# nrf7140_application register map
Vendor: Nordic Semiconductor; Series: nRF71; File version: 1
CPU: CM33 r0p4, little endian, MPU, FPU, 3 interrupt priority bits, 480 interrupts, 8 SAU regions
Registers are 32-bit, read-write, reset 0x0 unless marked. A register's access mark holds for its fields unless they carry their own. Offsets are from the block's base; [hi:lo] are bit positions; lines under a group give offsets from that group; {n}, {i} and the like mark numbered series; 'fields as' and 'values as' point back to an identical list.

## GLOBAL_QSPI120_NS — Quad serial peripheral interface 0
Base 0x4F8D7000
Same registers: GLOBAL_QSPI121_NS 0x4F8DF000, GLOBAL_QSPI120_S 0x5F8D7000, GLOBAL_QSPI121_S 0x5F8DF000
0x00 TASKS_START wo — Start operation.
  [0] TASKS_START
    1=Trigger task
0x100 EVENTS_CORE — Interrupt from the QSPI core
  [0] EVENTS_CORE
    0=NotGenerated (Event not generated); 1=Generated (Event generated)
0x104 EVENTS_DMA group — Peripheral events.
  0x00 EVENTS_DONE group — Peripheral events.
    0x00 LIST — Descriptor list is complete.
      [0] LIST
        values as EVENTS_CORE.EVENTS_CORE
    0x04 LISTPART — Descriptor list is partially complete. Threshold in CONFIG.LISTPARTTHRESH register has been passed.
      [0] LISTPART
        values as EVENTS_CORE.EVENTS_CORE
    0x08 SELECTJOB — Selected job is completed. Selection is done via CONFIG.SELECTJOBENABLE.
      [0] SELECTJOB
        values as EVENTS_CORE.EVENTS_CORE
    0x0C DATA — A job has been completed, i.e. the job's data has been completely transferred either to AXI or DMA bus, depending on direction.
      [0] DATA
        values as EVENTS_CORE.EVENTS_CORE
    0x10 JOB — A job has been fetched from the joblist.
      [0] JOB
        values as EVENTS_CORE.EVENTS_CORE
  0x14 ERROR — AXI bus error received.
    [0] ERROR
      values as EVENTS_CORE.EVENTS_CORE
  0x18 PAUSED — DMA paused with task TASKS_PAUSE.
    [0] PAUSED
      values as EVENTS_CORE.EVENTS_CORE
  0x1C RESET — DMA reset with task TASKS_RESET.
    [0] RESET
      values as EVENTS_CORE.EVENTS_CORE
  0x20 DONE — DMA transfer done
    [0] DONE
      values as EVENTS_CORE.EVENTS_CORE
  0x24 TXUNEXPECTEDIDLE — The QSPI core has gone into idle state at an unexpected time, this can happen if the TX buffer underflows, this event is followed by either DONE or ABORTED event. Triggered by the CORE being idle while we still have data to transfer to the CORE.
    [0] TXUNEXPECTEDIDLE
      values as EVENTS_CORE.EVENTS_CORE
  0x28 INTERNALBUSERROR — An error occured during the transfer of data internally in the QSPI, followed by either DONE or ABORTED event. This event is generated on an AHB error response on the easyDMA towards the QSPI CORE. The BUSERROR address is not given in a register since the target register address is fixed.
    [0] INTERNALBUSERROR
      values as EVENTS_CORE.EVENTS_CORE
  0x2C ABORTED — The QSPI DMA has aborted due to an error given in a separate event, and has attempted to complete any ongoing transactions, and stopped. The QSPI DMA is ready for a new transaction.
    [0] ABORTED
      values as EVENTS_CORE.EVENTS_CORE
0x200 SHORTS — Shortcuts between local events and tasks
  [0] DMA_DONE_START — Shortcut between event DMA.DONE and task START
    0=Disabled (Disable shortcut); 1=Enabled (Enable shortcut)
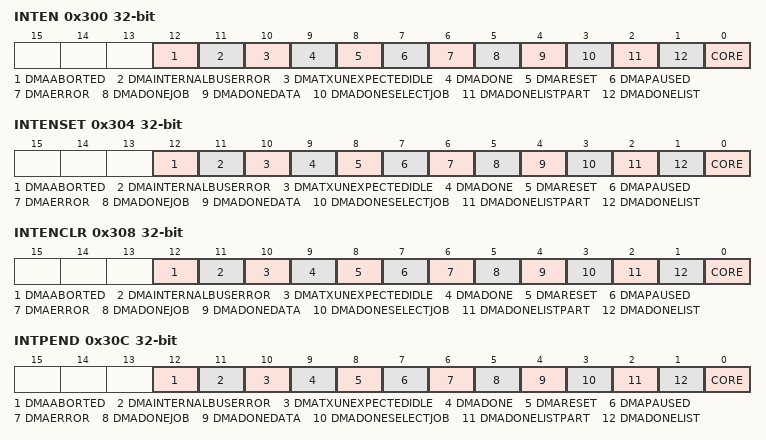
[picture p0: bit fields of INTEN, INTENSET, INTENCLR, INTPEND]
0x300 INTEN — Enable or disable interrupt
  [all] fields
    0=Disabled; 1=Enabled
  [12] DMAABORTED — Enable or disable interrupt for event DMAABORTED
  [11] DMAINTERNALBUSERROR — Enable or disable interrupt for event DMAINTERNALBUSERROR
  [10] DMATXUNEXPECTEDIDLE — Enable or disable interrupt for event DMATXUNEXPECTEDIDLE
  [9] DMADONE — Enable or disable interrupt for event DMADONE
  [8] DMARESET — Enable or disable interrupt for event DMARESET
  [7] DMAPAUSED — Enable or disable interrupt for event DMAPAUSED
  [6] DMAERROR — Enable or disable interrupt for event DMAERROR
  [5] DMADONEJOB — Enable or disable interrupt for event DMADONEJOB
  [4] DMADONEDATA — Enable or disable interrupt for event DMADONEDATA
  [3] DMADONESELECTJOB — Enable or disable interrupt for event DMADONESELECTJOB
  [2] DMADONELISTPART — Enable or disable interrupt for event DMADONELISTPART
  [1] DMADONELIST — Enable or disable interrupt for event DMADONELIST
  [0] CORE — Enable or disable interrupt for event CORE
0x304 INTENSET — Enable interrupt
  [all] fields
    on read: 0=Disabled (Read: Disabled); 1=Enabled (Read: Enabled) | on write: 1=Set (Enable)
  [12] DMAABORTED — Write '1' to enable interrupt for event DMAABORTED
  [11] DMAINTERNALBUSERROR — Write '1' to enable interrupt for event DMAINTERNALBUSERROR
  [10] DMATXUNEXPECTEDIDLE — Write '1' to enable interrupt for event DMATXUNEXPECTEDIDLE
  [9] DMADONE — Write '1' to enable interrupt for event DMADONE
  [8] DMARESET — Write '1' to enable interrupt for event DMARESET
  [7] DMAPAUSED — Write '1' to enable interrupt for event DMAPAUSED
  [6] DMAERROR — Write '1' to enable interrupt for event DMAERROR
  [5] DMADONEJOB — Write '1' to enable interrupt for event DMADONEJOB
  [4] DMADONEDATA — Write '1' to enable interrupt for event DMADONEDATA
  [3] DMADONESELECTJOB — Write '1' to enable interrupt for event DMADONESELECTJOB
  [2] DMADONELISTPART — Write '1' to enable interrupt for event DMADONELISTPART
  [1] DMADONELIST — Write '1' to enable interrupt for event DMADONELIST
  [0] CORE — Write '1' to enable interrupt for event CORE
0x308 INTENCLR — Disable interrupt
  [all] fields
    on read: 0=Disabled (Read: Disabled); 1=Enabled (Read: Enabled) | on write: 1=Clear (Disable)
  [12] DMAABORTED — Write '1' to disable interrupt for event DMAABORTED
  [11] DMAINTERNALBUSERROR — Write '1' to disable interrupt for event DMAINTERNALBUSERROR
  [10] DMATXUNEXPECTEDIDLE — Write '1' to disable interrupt for event DMATXUNEXPECTEDIDLE
  [9] DMADONE — Write '1' to disable interrupt for event DMADONE
  [8] DMARESET — Write '1' to disable interrupt for event DMARESET
  [7] DMAPAUSED — Write '1' to disable interrupt for event DMAPAUSED
  [6] DMAERROR — Write '1' to disable interrupt for event DMAERROR
  [5] DMADONEJOB — Write '1' to disable interrupt for event DMADONEJOB
  [4] DMADONEDATA — Write '1' to disable interrupt for event DMADONEDATA
  [3] DMADONESELECTJOB — Write '1' to disable interrupt for event DMADONESELECTJOB
  [2] DMADONELISTPART — Write '1' to disable interrupt for event DMADONELISTPART
  [1] DMADONELIST — Write '1' to disable interrupt for event DMADONELIST
  [0] CORE — Write '1' to disable interrupt for event CORE
0x30C INTPEND ro — Pending interrupts
  [all] fields
    on read: 0=NotPending (Read: Not pending); 1=Pending (Read: Pending)
  [12] DMAABORTED — Read pending status of interrupt for event DMAABORTED
  [11] DMAINTERNALBUSERROR — Read pending status of interrupt for event DMAINTERNALBUSERROR
  [10] DMATXUNEXPECTEDIDLE — Read pending status of interrupt for event DMATXUNEXPECTEDIDLE
  [9] DMADONE — Read pending status of interrupt for event DMADONE
  [8] DMARESET — Read pending status of interrupt for event DMARESET
  [7] DMAPAUSED — Read pending status of interrupt for event DMAPAUSED
  [6] DMAERROR — Read pending status of interrupt for event DMAERROR
  [5] DMADONEJOB — Read pending status of interrupt for event DMADONEJOB
  [4] DMADONEDATA — Read pending status of interrupt for event DMADONEDATA
  [3] DMADONESELECTJOB — Read pending status of interrupt for event DMADONESELECTJOB
  [2] DMADONELISTPART — Read pending status of interrupt for event DMADONELISTPART
  [1] DMADONELIST — Read pending status of interrupt for event DMADONELIST
  [0] CORE — Read pending status of interrupt for event CORE
0x400 ENABLE — Enables the QSPI This requests clock for the IP core
  [0] ENABLE — Enable the QSPI
0x404 CONFIG group — Unspecified
  0x00 TXBURSTLENGTH reset 0x8 — Transmit burst length
    [4:0] AMOUNT — Number of buffer lines
  0x04 RXBURSTLENGTH reset 0x8 — Receive burst length
    [4:0] AMOUNT — Number of buffer lines
  0x08 RXTRANSFERLENGTH reset 0x10 — Receive transfer full length
    [17:0] AMOUNT — Number of buffer lines
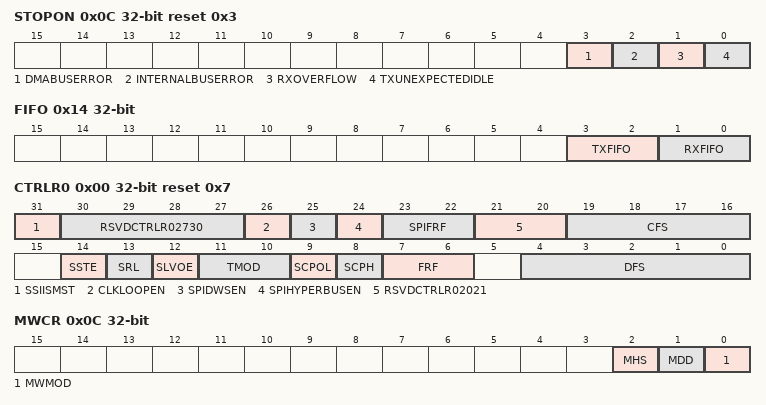
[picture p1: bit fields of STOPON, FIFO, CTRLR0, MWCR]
  0x0C STOPON reset 0x3 — Stop the DMA if the CORE goes into any of the enabled states.
    [3] DMABUSERROR — Terminate the transaction if a DMA.ERROR event is detected.
      0=Disabled; 1=Enabled
    [2] INTERNALBUSERROR — Terminate the transaction if a INTERNALBUSERROR event is detected.
      0=Disabled; 1=Enabled
    [1] RXOVERFLOW — This condition occurrs if the DMA attempts to write to the RX buffer in the CORE, but the buffer is full. When this bit is enabled the DMA will stop when the CORE buffer experiences a rx buffer overflow
      0=Disabled (Stop on rx overflow disabled.); 1=Enabled (Stop on rx overflow enabled.)
    [0] TXUNEXPECTEDIDLE — The CORE will go into idle if the CORE buffer is emptied, if the DMA still has data to transfer the CORE is not expected to go into idle state. This constitutes a buffer underflow. The CORE migth also go into idle if an error occurs.
      0=Disabled (Stop on tx unexpected idle disabled.); 1=Enabled (Stop on tx unexpected idle enabled.)
  0x10 AXIMODE — Determines if AXI-lite or full AXI is used.
    [4] AXIMODE — Type of AXI access.
      0=Lite (AXI Lite); 1=Full AXI
0x418 FORMAT group — Unspecified
  0x00 DFS — Data frame size
    [5:0] DFS
  0x04 BPP — Bits per pixel
    [5:0] BPP
      0=Reordering of pixels disabled; 4=4 Bits per pixel; 8=8 Bits per pixel; 16=16 Bits per pixel
  0x08 PIXELS — Number of pixels following the command
    [17:0] PIXELS — Number of pixels
  0x0C CILEN — Command/Instruction length
    [1:0] CILEN — Number of words
0x500 DMA group — Unspecified
  0x00 STATUS group — EasyVDMA status registers.
    0x00 BYTECOUNT ro — Number of bytes sent or received during processing of current descriptor list
    0x04 ATTRIBUTE ro — Latest job attribute being processed.
      [5:0] ATTRIBUTE
    0x08 ADDRESS ro — Latest address being accessed.
    0x0C JOBCOUNT ro — Number of completed jobs in current descriptor list.
    0x10 BUSERROR ro — AXI bus error status.
      [2:0] BUSERROR — AXI bus error type
        0=NoError (There are no errors.); 1=ReadError (Error related to memory when reading joblist, or error related to memory/register when reading data.); 2=ReadDecodeError (Error related to the joblist address when reading joblist, or error related to address when reading memory/register.); 3=WriteError (Error related to memory/register when writing data.); 4=WriteDecodeError (Error related to the memory/register address when writing data.)
    0x14 FIFO ro — Data fifo status.
      [3:2] TXFIFO — Peripheral-to-Memory direction data fifo status
        0=Empty (Fifo is empty.); 1=NotEmpty (Fifo contains data.); 2=Full (Fifo is full.)
      [1:0] RXFIFO — Memory-to-Peripheral direction data fifo status
        values as TXFIFO
    0x18 ACTIVE ro — DMA activity state.
      [0] ACTIVE
        0=Idle (DMA is in idle state.); 1=Active (Data is being transferred.)
  0x100 CONFIG group — General config registers
    0x00 BUFFERFILL — Data to be used when data is sent with BufferFill attribute
      [7:0] BUFFERFILL
    0x04 LISTPTR — Start address of descriptor list
    0x08 LISTPARTTHRESH — Threshold value for generating event EVENTS_DONE.PARTLIST when descriptor list is partially completed. Value is number of jobs.
      [15:0] LISTPARTTHRESH — Threshold value.
0x900 CORE group — Unspecified
  0x00 CORE group — Unspecified
    0x00 CTRLR0 reset 0x7 — Control Register 0
      [31] SSIISMST ro — This field selects if QSPI CORE is working in Controller or Target mode
        0=TARGET (QSPI CORE is Target); 1=CONTROLLER (QSPI CORE is Controller)
      [30:27] RSVDCTRLR02730 ro
      [26] CLKLOOPEN ro — Clock loop back enable bit. Once this bit is set to 1, QSPI CORE will use looped back clock (mst_sclk_in) to capture read data
        0=DISABLE (Disable Clock Loop Back); 1=ENABLE (Enable Clock Loop Back)
      [25] SPIDWSEN — Enable Dynamic wait states in SPI mode of operation. This field is only applicable when CTRLR0.FRF is set to 0 (Motorola SPI Frame Format).
        0=DISABLE (Disable SPI Dynamic Wait State); 1=ENABLE (Enable SPI Dynamic Wait State)
      [24] SPIHYPERBUSEN ro — SPI Hyperbus Frame format enable.
        0=DISABLE (Disable Hyperbus Format); 1=ENABLE (Enable Hyperbus Format)
      [23:22] SPIFRF — SPI Frame Format
        0=SPISTANDARD (Standard SPI Format); 1=SPIDUAL (Dual SPI Format); 2=SPIQUAD (Quad SPI Format); 3=SPIOCTAL (Octal SPI Format)
      [21:20] RSVDCTRLR02021 ro
      [19:16] CFS — Control Frame Size.
        {v}=SIZE{v+1:02}BIT ({v+1:02}-bit Control Word) (v=0..15)
      [14] SSTE — Target Select Toggle Enable.
        0=TOGGLEDISABLE (ss_*_n will stay low and sclk will run continuously for the duration of the transfer); 1=TOGGLEEN (ss_*_n line will toggle between consecutive data frames, with the serial clock (sclk) being held to its default value while ss_*_n is high)
      [13] SRL — Shift Register Loop.
        0=NORMALMODE (Normal mode operation); 1=TESTINGMODE (Test Mode Operation)
      [12] SLVOE — Target Output Enable.
        0=ENABLED (Target Output is enabled); 1=DISABLED (Target Output is disabled)
      [11:10] TMOD — Transfer Mode.
        0=TXANDRX (Transmit & Receive; Not Applicable in enhanced SPI operating mode or when SSIC_HAS_TX_RX_EN is set to 0); 1=TXONLY (Transmit only mode; Or Write in enhanced SPI operating mode); 2=RXONLY (Receive only mode; Or Read in enhanced SPI operating mode); 3=EEPROMREAD (EEPROM Read mode; Not Applicable in enhanced SPI operating mode)
      [9] SCPOL — Serial Clock Polarity.
        0=INACTIVEHIGH (Inactive state of serial clock is low); 1=INACTIVELOW (Inactive state of serial clock is high)
      [8] SCPH — Serial Clock Phase.
        0=MIDDLEBIT (Serial clock toggles in middle of first bit); 1=STARTBIT (Serial clock toggles at start of first bit)
      [7:6] FRF — Frame Format.
        0=SPI (Motorola SPI Frame Format); 1=SSP (Texas Instruments SSP Frame Format); 2=MICROWIRE (National Semiconductors Microwire Frame Format)
      [4:0] DFS — Data Frame Size.
        {v}=DFS{v+1:02}BIT ({v+1:02}-bit serial data transfer) (v=3..31)
    0x04 CTRLR1 — Control Register 1
      [15:0] NDF — Number of Data Frames.
    0x08 SSIENR — SSI Enable Register
      [0] SSICEN — SSI Enable.
        0=DISABLE (Disables QSPI CORE); 1=ENABLED (Enables QSPI CORE)
    0x0C MWCR — Microwire Control Register
      [2] MHS — Microwire Handshaking.
        0=DISABLE (handshaking interface is disabled); 1=ENABLED (handshaking interface is enabled)
      [1] MDD — Microwire Control.
        0=RECEIVE (SSI receives data); 1=TRANSMIT (SSI transmits data)
      [0] MWMOD — Microwire Transfer Mode.
        0=NONSEQUENTIAL (Non-Sequential Transfer); 1=SEQUENTIAL (Sequential Transfer)
    0x10 SER — Target Enable Register
      [3:0] SER — Chip Select Enable Flag.
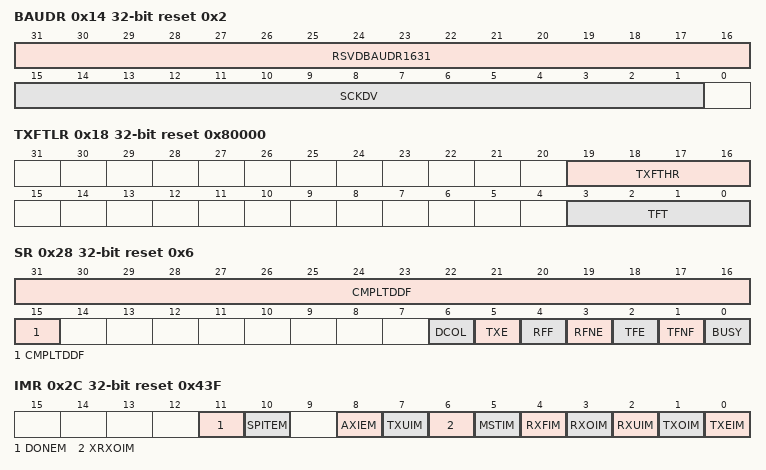
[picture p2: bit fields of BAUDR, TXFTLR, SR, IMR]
    0x14 BAUDR reset 0x2 — Baud Rate Select
      [31:16] RSVDBAUDR1631 ro
      [15:1] SCKDV — SSI Clock Divider.
    0x18 TXFTLR reset 0x80000 — Transmit FIFO Threshold Level
      [19:16] TXFTHR — Transfer start FIFO level.
      [3:0] TFT — Transmit FIFO Threshold.
    0x1C RXFTLR — Receive FIFO Threshold Level
      [3:0] RFT — Receive FIFO Threshold.
    0x20 TXFLR — Transmit FIFO Level Register
      [4:0] TXTFL ro — Transmit FIFO Level.
    0x24 RXFLR — Receive FIFO Level Register
      [4:0] RXTFL ro — Receive FIFO Level.
    0x28 SR reset 0x6 — Status Register
      [31:15] CMPLTDDF ro — Completed Data frames
      [6] DCOL ro — Data Collision Error.
        0=NOERRORCONDITION; 1=TXCOLLISIONERROR (Transmit Data Collision Error)
      [5] TXE ro — Transmission Error.
        0=NOERROR; 1=TXERROR (Transmission Error)
      [4] RFF ro — Receive FIFO Full.
        0=NOTFULL (Receive FIFO is not full); 1=FULL (Receive FIFO is full)
      [3] RFNE ro — Receive FIFO Not Empty.
        0=EMPTY (Receive FIFO is empty); 1=NOTEMPTY (Receive FIFO is not empty)
      [2] TFE ro — Transmit FIFO Empty.
        0=NOTEMPTY (Transmit FIFO is not empty); 1=EMPTY (Transmit FIFO is empty)
      [1] TFNF ro — Transmit FIFO Not Full.
        0=FULL (Tx FIFO is full); 1=NOTFULL (Tx FIFO is not Full)
      [0] BUSY ro — SSI Busy Flag.
        0=INACTIVE (QSPI CORE is idle or disabled); 1=ACTIVE (QSPI CORE is actively transferring data)
    0x2C IMR reset 0x43F — Interrupt Mask Register
      [11] DONEM ro — SSI Done Interrupt Mask
        0=MASKED (ssi_done_intr interrupt is masked); 1=UNMASKED (ssi_done_intr interrupt is not masked)
      [10] SPITEM — SPI Transmit Error Interrupt Mask
        0=MASKED (ssi_spite_intr interrupt is masked); 1=UNMASKED (ssi_spite_intr interrupt is not masked)
      [8] AXIEM ro — AXI Error Interrupt Mask
        0=MASKED (ssi_axie_intr interrupt is masked); 1=UNMASKED (ssi_axie_intr interrupt is not masked)
      [7] TXUIM ro — Transmit FIFO Underflow Interrupt Mask
        0=MASKED (ssi_txu_intr interrupt is masked); 1=UNMASKED (ssi_txu_intr interrupt is not masked)
      [6] XRXOIM ro — XIP Receive FIFO Overflow Interrupt Mask
        0=MASKED (ssi_xrxo_intr interrupt is masked); 1=UNMASKED (ssi_xrxo_intr interrupt is not masked)
      [5] MSTIM — Multi-Controller Contention Interrupt Mask. This bit field is not present if the QSPI CORE is configured as a serial-controller device.
        0=MASKED (ssi_mst_intr interrupt is masked); 1=UNMASKED (ssi_mst_intr interrupt is not masked)
      [4] RXFIM — Receive FIFO Full Interrupt Mask
        0=MASKED (ssi_rxf_intr interrupt is masked); 1=UNMASKED (ssi_rxf_intr interrupt is not masked)
      [3] RXOIM — Receive FIFO Overflow Interrupt Mask
        0=MASKED (ssi_rxo_intr interrupt is masked); 1=UNMASKED (ssi_rxo_intr interrupt is not masked)
      [2] RXUIM — Receive FIFO Underflow Interrupt Mask
        0=MASKED (ssi_rxu_intr interrupt is masked); 1=UNMASKED (ssi_rxu_intr interrupt is not masked)
      [1] TXOIM — Transmit FIFO Overflow Interrupt Mask
        0=MASKED (ssi_txo_intr interrupt is masked); 1=UNMASKED (ssi_txo_intr interrupt is not masked)
      [0] TXEIM — Transmit FIFO Empty Interrupt Mask
        0=MASKED (ssi_txe_intr interrupt is masked); 1=UNMASKED (ssi_txe_intr interrupt is not masked)
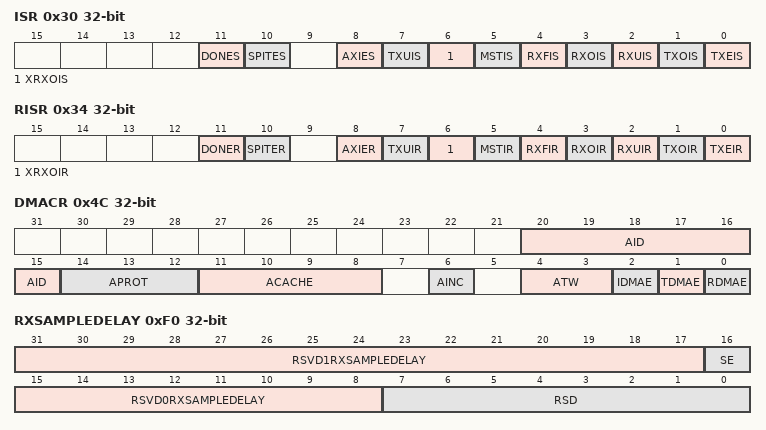
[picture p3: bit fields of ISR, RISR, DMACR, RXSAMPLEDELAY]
    0x30 ISR — Interrupt Status Register
      [11] DONES ro — SSI Done Interrupt Status
        0=INACTIVE (ssi_done_intr interrupt is not active after masking); 1=ACTIVE (ssi_done_intr interrupt is active after masking)
      [10] SPITES ro — SPI Transmit Error Interrupt
        0=INACTIVE (ssi_spite_intr interrupt is not active after masking); 1=ACTIVE (ssi_spite_intr interrupt is active after masking)
      [8] AXIES ro — AXI Error Interrupt Status
        0=INACTIVE (ssi_axie_intr interrupt is not active after masking); 1=ACTIVE (ssi_axie_intr interrupt is active after masking)
      [7] TXUIS ro — Transmit FIFO Underflow Interrupt Status
        0=INACTIVE (ssi_txu_intr interrupt is not active after masking); 1=ACTIVE (ssi_txu_intr interrupt is active after masking)
      [6] XRXOIS ro — XIP Receive FIFO Overflow Interrupt Status
        0=INACTIVE (ssi_xrxo_intr interrupt is not active after masking); 1=ACTIVE (ssi_xrxo_intr interrupt is active after masking)
      [5] MSTIS ro — Multi-Controller Contention Interrupt Status. This bit field is not present
        0=INACTIVE (ssi_mst_intr interrupt is not active after masking); 1=ACTIVE (ssi_mst_intr interrupt is active after masking)
      [4] RXFIS ro — Receive FIFO Full Interrupt Status
        0=INACTIVE (ssi_rxf_intr interrupt is not active after masking); 1=ACTIVE (ssi_rxf_intr interrupt is active after masking)
      [3] RXOIS ro — Receive FIFO Overflow Interrupt Status
        0=INACTIVE (ssi_rxo_intr interrupt is not active after masking); 1=ACTIVE (ssi_rxo_intr interrupt is active after masking)
      [2] RXUIS ro — Receive FIFO Underflow Interrupt Status
        0=INACTIVE (ssi_rxu_intr interrupt is not active after masking); 1=ACTIVE (ssi_rxu_intr interrupt is active after masking)
      [1] TXOIS ro — Transmit FIFO Overflow Interrupt Status
        0=INACTIVE (ssi_txo_intr interrupt is not active after masking); 1=ACTIVE (ssi_txo_intr interrupt is active after masking)
      [0] TXEIS ro — Transmit FIFO Empty Interrupt Status
        0=INACTIVE (ssi_txe_intr interrupt is not active after masking); 1=ACTIVE (ssi_txe_intr interrupt is active after masking)
    0x34 RISR — Raw Interrupt Status Register
      [11] DONER ro — SSI Done Interrupt Raw Status
        0=INACTIVE (ssi_done_intr interrupt is not active prior masking); 1=ACTIVE (ssi_done_intr interrupt is active prior to masking)
      [10] SPITER ro — SPI Transmit Error Interrupt status.
        0=INACTIVE (ssi_spite_intr interrupt is not active prior to masking); 1=ACTIVE (ssi_spite_intr interrupt is active prior to masking)
      [8] AXIER ro — AXI Error Interrupt Raw Status
        0=INACTIVE (ssi_axie_intr interrupt is not active prior masking); 1=ACTIVE (ssi_axie_intr interrupt is active prior to masking)
      [7] TXUIR ro — Transmit FIFO Underflow Interrupt Raw Status
        0=INACTIVE (ssi_txu_intr interrupt is not active prior masking); 1=ACTIVE (ssi_txu_intr interrupt is active prior to masking)
      [6] XRXOIR ro — XIP Receive FIFO Overflow Raw Interrupt Status
        0=INACTIVE (ssi_xrxo_intr interrupt is not active prior masking); 1=ACTIVE (ssi_xrxo_intr interrupt is active prior to masking)
      [5] MSTIR ro — Multi-Controller Contention Raw Interrupt Status. This bit field is not present if the QSPI CORE is configured as a serial-target device.
        0=INACTIVE (ssi_mst_intr interrupt is not active prior masking); 1=ACTIVE (ssi_mst_intr interrupt is active prior to masking)
      [4] RXFIR ro — Receive FIFO Full Raw Interrupt Status
        0=INACTIVE (ssi_rxf_intr interrupt is not active prior masking); 1=ACTIVE (ssi_rxf_intr interrupt is active prior to masking)
      [3] RXOIR ro — Receive FIFO Overflow Raw Interrupt Status
        0=INACTIVE (ssi_rxo_intr interrupt is not active prior masking); 1=ACTIVE (ssi_rxo_intr interrupt is active prior to masking)
      [2] RXUIR ro — Receive FIFO Underflow Raw Interrupt Status
        0=INACTIVE (ssi_rxu_intr interrupt is not active prior masking); 1=ACTIVE (ssi_rxu_intr interrupt is active prior to masking)
      [1] TXOIR ro — Transmit FIFO Overflow Raw Interrupt Status
        0=INACTIVE (ssi_txo_intr interrupt is not active prior masking); 1=ACTIVE (ssi_txo_intr interrupt is active prior to masking)
      [0] TXEIR ro — Transmit FIFO Empty Raw Interrupt Status
        0=INACTIVE (ssi_txe_intr interrupt is not active prior masking); 1=ACTIVE (ssi_txe_intr interrupt is active prior to masking)
    0x38 TXEICR — Transmit FIFO Error Interrupt Clear Register Register
      [0] TXEICR ro — Clear Transmit FIFO Overflow/Underflow Interrupt.
    0x3C RXOICR — Receive FIFO Overflow Interrupt Clear Register
      [0] RXOICR ro — Clear Receive FIFO Overflow Interrupt.
    0x40 RXUICR — Receive FIFO Underflow Interrupt Clear Register
      [0] RXUICR ro — Clear Receive FIFO Underflow Interrupt.
    0x44 MSTICR — Multi-Controller Interrupt Clear Register
      [0] MSTICR ro — Clear Multi-Controller Contention Interrupt.
    0x48 ICR — Interrupt Clear Register
      [0] ICR ro — Clear Interrupts.
    0x4C DMACR — DMA Control Register
      [20:15] AID ro — AXI awid/arid signal value.
      [14:12] APROT ro — AXI arprot/awprot signal value.
      [11:8] ACACHE ro — AXI arcache/awcache signal value.
      [6] AINC ro — Address Increment. Indicates whether to increment the AXI address on every transfer.
      [4:3] ATW ro — AXI transfer width for DMA transfers mapped to arsize/awsize. This value must be less than or equal to SSIC_AXI_DW. Values:
      [2] IDMAE ro — Internal DMA Enable. This bit should be enabled only when CTRLR0.FRF = 0 (Motorola SPI) and CTRLR0.SPI_FRF > 0.
      [1] TDMAE — Transmit DMA Enable. This bit enables/disables the transmit FIFO DMA channel.
        0=DISABLE (Transmit DMA disabled); 1=ENABLED (Transmit DMA enabled)
      [0] RDMAE — Receive DMA Enable. This bit enables/disables the receive FIFO DMA channel.
        0=DISABLE (Receive DMA disabled); 1=ENABLED (Receive DMA enabled)
    0x50 DMATDLR — DMA Transmit Data Level
      [3:0] DMATDL — Transmit Data Level. This bit field controls the level at which a DMA request is made by the transmit logic. It is equal to the watermark level; that is, the dma_tx_req signal is generated when the number of valid data entries in the transmit FIFO is equal to or below this field value, and TDMAE = 1.
    0x54 DMARDLR — DMA Receive Data Level
      [3:0] DMARDL — Receive Data Level. This bit field controls the level at which a DMA request is made by the receive logic. The watermark level = DMARDL+1; that is, dma_rx_req is generated when the number of valid data entries in the receive FIFO is equal to or above this field value + 1, and RDMAE=1.
    0x58 IDR reset 0x51535049 — Identification Register
      [31:0] IDCODE ro — Identification code. The register contains the identification code of the peripheral, which is written into the register at configuration time using CoreConsultant.
    0x5C SSICVERSIONID reset 0x3230302A — QSPI CORE component version
      [31:0] SSICCOMPVERSION ro — Contains the hex representation of the Synopsys component version. Consists of ASCII value for each number in the version, followed by *. For example 31_30_33_2A represents the version 1.03*.
    {0x60+4k} DR[{k}] (k=0..35) — Description collection: QSPI CORE Data Register
      [31:0] DR — Data Register. When writing to this register, you must right-justify the data. Read data are automatically right-justified.
    0xF0 RXSAMPLEDELAY
      [31:17] RSVD1RXSAMPLEDELAY ro
      [16] SE — Receive Data (rxd) Sampling Edge. This register is used to decide the sampling edge for RXD signal with ssi_clk. Then this bit is set to 1 then negative edge of ssi_clk will be used to sample the incoming data, otherwise positive edge will be used for sampling.
      [15:8] RSVD0RXSAMPLEDELAY ro
      [7:0] RSD — Receive Data (rxd) Sample Delay. This register is used to delay the sample of the rxd input port. Each value
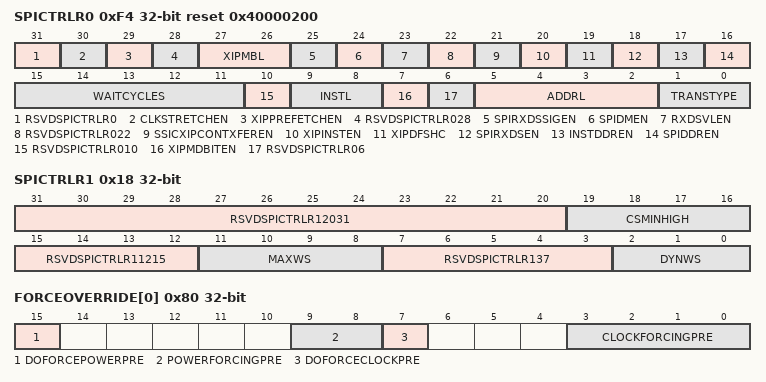
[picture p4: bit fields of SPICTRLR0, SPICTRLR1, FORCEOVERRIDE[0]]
    0xF4 SPICTRLR0 reset 0x40000200 — SPI_CTRLR0 - SPI Control Register
      [31] RSVDSPICTRLR0 ro
      [30] CLKSTRETCHEN — Enables clock stretching capability in SPI transfers.
      [29] XIPPREFETCHEN ro — Enables XIP pre-fetch functionality in QSPI CORE.
      [28] RSVDSPICTRLR028 ro
      [27:26] XIPMBL ro — XIP Mode bits length. Sets the length of mode bits in XIP mode of operation. These bits are valid only when SPI_CTRLR0.XIP_MD_BIT_EN is set to 1.
        0=MBL2 (Mode bits length equal to 2); 1=MBL4 (Mode bits length equal to 4); 2=MBL8 (Mode bits length equal to 8); 3=MBL16 (Mode bits length equal to 16)
      [25] SPIRXDSSIGEN ro — Enable rxds signaling during address and command phase of Hyperbus transfer.
      [24] SPIDMEN ro — SPI data mask enable bit.
      [23] RXDSVLEN ro — RXDS variable latency enable bit.
      [22] RSVDSPICTRLR022 ro
      [21] SSICXIPCONTXFEREN ro — Enable continuous transfer in XIP mode. If this bit is set to 1 then continuous transfer mode in XIP will be enabled, in this mode QSPI CORE will keep target selected until a non-XIP transfer is detected on the AHB interface.
      [20] XIPINSTEN ro — XIP instruction enable bit. If this bit is set to 1 then XIP transfers will also have instruction phase. The instruction op-codes will be chosen from XIP_INCR_INST or XIP_WRAP_INST registers bases on AHB transfer type.
      [19] XIPDFSHC ro — Fix DFS for XIP transfers. If this bit is set to 1 then data frame size for XIP transfers will be fixed to the programmed value in CTRLR0.DFS. The number of data frames to fetch will be determined by HSIZE and HBURST signals. If this bit is set to 0 then data frame size and number of data frames to fetch will be determined by HSIZE and HBURST signals
      [18] SPIRXDSEN ro — Read data strobe enable bit. Once this bit is set to 1 QSPI CORE will use Read data strobe (rxds) to capture read data.
      [17] INSTDDREN ro — Instruction DDR Enable bit. This will enable Dual-data rate transfer for Instruction phase.
      [16] SPIDDREN ro — SPI DDR Enable bit. This will enable Dual-data rate transfers in Enhanced SPI frame formats of SPI.
      [15:11] WAITCYCLES — Wait cycles in Enhanced SPI mode between control frames transmit and data reception. Specified as number of SPI clock cycles.
      [10] RSVDSPICTRLR010 ro
      [9:8] INSTL — Enhanced SPI mode instruction length in bits.
        0=No Instruction; 1=4 bit Instruction length; 2=8 bit Instruction length; 3=16 bit Instruction length
      [7] XIPMDBITEN ro — Mode bits enable in XIP mode. If this bit is set to 1, then in XIP mode of operation QSPI CORE will insert mode bits after the address phase. These bits are set in register XIP_MODE_BITS register.
      [6] RSVDSPICTRLR06 ro
      [5:2] ADDRL — This bit defines Length of Address to be transmitted. Only after this much bits are programmed in to the FIFO the transfer can begin.
        0=No Address; 1=4 bit Address length; 2=8 bit Address length; 3=12 bit Address length; 4=16 bit Address length; 5=20 bit Address length; 6=24 bit Address length; 7=28 bit Address length; 8=32 bit Address length; 9=36 bit Address length; 10=40 bit Address length; 11=44 bit Address length; 12=48 bit Address length; 13=52 bit Address length; 14=56 bit Address length; 15=60 bit Address length
      [1:0] TRANSTYPE — Address and instruction transfer format.
        0=TT0 (Instruction and Address will be sent in Standard SPI Mode.); 1=TT1 (Instruction will be sent in Standard SPI Mode and Address will be sent in the mode specified by CTRLR0.SPI_FRF.); 2=TT2 (Both Instruction and Address will be sent in the mode specified by SPI_FRF.); 3=TT3 (Dual Octal mode, the address and instruction are transferred in octal mode and data is transferred on 16 data lines.)
  0x100 DWCSSIADDRESSBLOCK2 group — Unspecified
    0x18 SPICTRLR1 — SPI Control 1 register
      [31:20] RSVDSPICTRLR12031 ro
      [19:16] CSMINHIGH — Chip-Select Minimum HIGH period.
      [15:12] RSVDSPICTRLR11215 ro
      [11:8] MAXWS — Maximum wait cycles allowed per transaction.
      [7:3] RSVDSPICTRLR137 ro
      [2:0] DYNWS — SPI Dynamic Wait states field.
    0x1C SPITECR — SPI Transmit Error Interrupt Clear Register
      [0] SPITECR ro — Clear SPI Transmit Error interrupt.
0xF00 PCGCS group — Unspecified
  {0x0+4j} PENALTY[{j}] (j=0..0) reset 0xFFFFFFFC — Description collection: Penalty level for power/clock pair n. When FULL_PCP_ZERO feature is not supported, PENALTY[0] address overlaps the PENALTY0 address and register description for PENALTY[0] is not valid.
    [1:0] PENALTY — Penalty level
  0x00 PENALTY0 (alternate view of PENALTY[*]) — Penalty level for power/clock pair 0. The register description is valid only when FULL_PCP_ZERO feature is not supported
    [1:0] PENALTY ro — Penalty level
  {0x80+4j} FORCEOVERRIDE[{j}] (j=0..0) — Description collection: Force override of power/clock pair n.
    [15] DOFORCEPOWERPRE, [9:8] POWERFORCINGPRE, [7] DOFORCECLOCKPRE, [3:0] CLOCKFORCINGPRE
